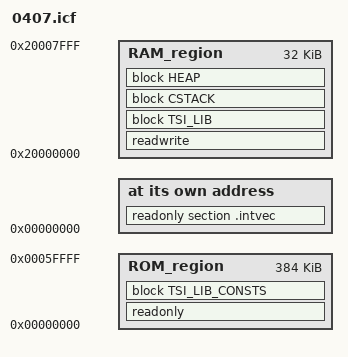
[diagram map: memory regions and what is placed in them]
/*###ICF### Section handled by ICF editor, don't touch! ****/
/*-Editor annotation file-*/
/* IcfEditorFile="$TOOLKIT_DIR$\config\ide\IcfEditor\cortex_v1_0.xml" */
/*-Specials-*/
define symbol __ICFEDIT_intvec_start__ = 0x00000000;
/*-Memory Regions-*/
define symbol __ICFEDIT_region_ROM_start__ = 0x00000000;
define symbol __ICFEDIT_region_ROM_end__   = 0x0005FFFF;
define symbol __ICFEDIT_region_RAM_start__ = 0x20000000;
define symbol __ICFEDIT_region_RAM_end__   = 0x20007FFF;
/*-Sizes-*/
define symbol __ICFEDIT_size_cstack__ = 0x800;
define symbol __ICFEDIT_size_heap__   = 0x0;
/**** End of ICF editor section. ###ICF###*/

define memory mem with size = 4G;
define region ROM_region   = mem:[from __ICFEDIT_region_ROM_start__   to __ICFEDIT_region_ROM_end__];							
define region RAM_region   = mem:[from __ICFEDIT_region_RAM_start__   to __ICFEDIT_region_RAM_end__];								
								
define block CSTACK    with alignment = 8, size = __ICFEDIT_size_cstack__   { };
define block HEAP      with alignment = 8, size = __ICFEDIT_size_heap__     { };

/* TSI library blocks (for tuner and debugging). */
define block TSI_LIB_CONSTS with alignment = 4, fixed order { 
    section "tsi.const.00_lib_handle",
    section "tsi.const.01_widgets", 
    section "tsi.const.02_sensors", 
    section "tsi.const.03_widget_ptrs", 
    section "tsi.const.04_sensor_ptrs", 
    section "tsi.const.05_meta_widgets", 
    section "tsi.const.06_meta_sensors", 
    section "tsi.const.07_driver", 
    section "tsi.const.08_miscs",
    section "tsi.const.09_scangroup.0_begin",
    section "tsi.const.09_scangroup.1_group",
    section "tsi.const.10_desc_conf",
    section "tsi.const.11_plugins.0_begin",
    section "tsi.const.11_plugins.1_cb.0",
    section "tsi.const.11_plugins.1_cb.1",
    section "tsi.const.11_plugins.1_cb.2",
    section "tsi.const.11_plugins.1_cb.3",
    section "tsi.const.11_plugins.1_cb.4",
    section "tsi.const.11_plugins.1_cb.5",
    section "tsi.const.11_plugins.1_cb.6",
    section "tsi.const.11_plugins.1_cb.7",
    section "tsi.const.11_plugins.2_end",
};

define block TSI_LIB with alignment = 4, fixed order { 
    section "tsi.00_lib_handle", 
    section "tsi.01_widgets", 
    section "tsi.02_sensors", 
    section "tsi.03_driver", 
    section "tsi.04_miscs" 
};

initialize by copy { readwrite };
do not initialize  { section .noinit };

place at address mem:__ICFEDIT_intvec_start__ { readonly section .intvec };

place in ROM_region   { readonly, 
                        block TSI_LIB_CONSTS };
place in RAM_region   { readwrite, 
                        block TSI_LIB,
                        block CSTACK, block HEAP };

export symbol __ICFEDIT_region_RAM_start__;
export symbol __ICFEDIT_region_RAM_end__;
